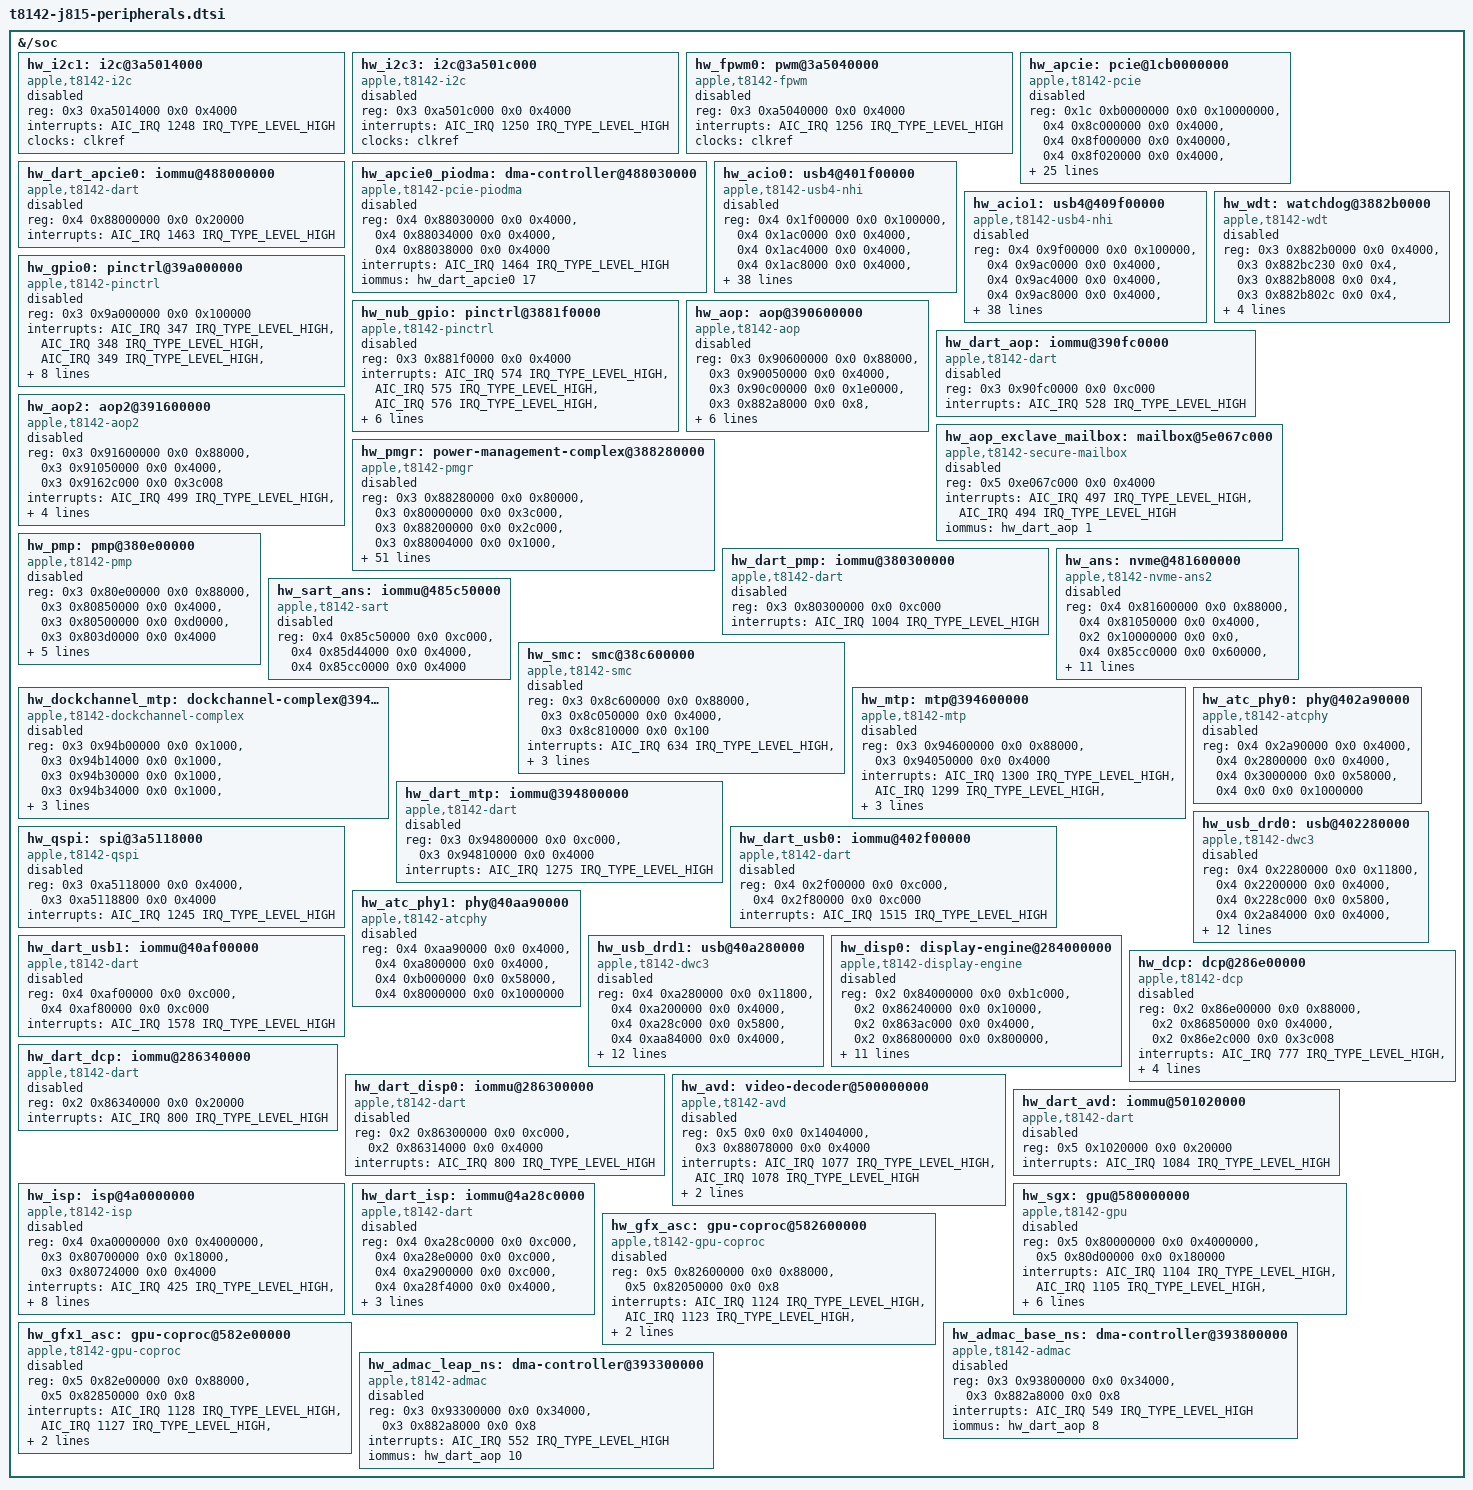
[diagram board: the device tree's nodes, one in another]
#include "t8142-peripherals.dtsi"

// SPDX-License-Identifier: GPL-2.0+ OR MIT
/* Register and interrupt resources; ownership-sensitive blocks stay disabled. */

&{/soc} {

	hw_i2c1: i2c@3a5014000 {
		compatible = "apple,t8142-i2c", "apple,t8103-i2c";
		reg = <0x3 0xa5014000 0x0 0x4000>;
		interrupts = <AIC_IRQ 1248 IRQ_TYPE_LEVEL_HIGH>;
		status = "disabled";
		clocks = <&clkref>;
		#address-cells = <1>;
		#size-cells = <0>;
	};

	hw_i2c3: i2c@3a501c000 {
		compatible = "apple,t8142-i2c", "apple,t8103-i2c";
		reg = <0x3 0xa501c000 0x0 0x4000>;
		interrupts = <AIC_IRQ 1250 IRQ_TYPE_LEVEL_HIGH>;
		status = "disabled";
		clocks = <&clkref>;
		#address-cells = <1>;
		#size-cells = <0>;
	};

	hw_fpwm0: pwm@3a5040000 {
		compatible = "apple,t8142-fpwm", "apple,s5l-fpwm";
		reg = <0x3 0xa5040000 0x0 0x4000>;
		interrupts = <AIC_IRQ 1256 IRQ_TYPE_LEVEL_HIGH>;
		status = "disabled";
		#pwm-cells = <2>;
		clocks = <&clkref>;
	};

	hw_apcie: pcie@1cb0000000 {
		compatible = "apple,t8142-pcie", "apple,pcie";
		reg = <0x1c 0xb0000000 0x0 0x10000000>,
		      <0x4 0x8c000000 0x0 0x4000>,
		      <0x4 0x8f000000 0x0 0x40000>,
		      <0x4 0x8f020000 0x0 0x4000>,
		      <0x4 0x8f040000 0x0 0x20000>,
		      <0x4 0x8e000000 0x0 0x1000000>,
		      <0x4 0x8d044000 0x0 0x4000>,
		      <0x4 0x8d980800 0x0 0x4000>,
		      <0x4 0x88028000 0x0 0x8000>,
		      <0x4 0x8803c000 0x0 0x4000>,
		      <0x4 0x8f010000 0x0 0x4000>,
		      <0x4 0x88024000 0x0 0x4000>,
		      <0x4 0x88048000 0x0 0x4000>,
		      <0x4 0x88044000 0x0 0x4000>,
		      <0x4 0x89028000 0x0 0x8000>,
		      <0x4 0x8903c000 0x0 0x4000>,
		      <0x4 0x8f014000 0x0 0x4000>,
		      <0x4 0x89024000 0x0 0x4000>,
		      <0x4 0x89048000 0x0 0x4000>,
		      <0x4 0x89044000 0x0 0x4000>,
		      <0x4 0x8a028000 0x0 0x8000>,
		      <0x4 0x8a03c000 0x0 0x4000>,
		      <0x4 0x8f018000 0x0 0x4000>,
		      <0x4 0x8a024000 0x0 0x4000>,
		      <0x4 0x8a048000 0x0 0x4000>,
		      <0x4 0x8a044000 0x0 0x4000>;
		interrupts = <AIC_IRQ 1462 IRQ_TYPE_LEVEL_HIGH>,
			     <AIC_IRQ 1471 IRQ_TYPE_LEVEL_HIGH>,
			     <AIC_IRQ 1480 IRQ_TYPE_LEVEL_HIGH>;
		status = "disabled";
	};

	hw_dart_apcie0: iommu@488000000 {
		compatible = "apple,t8142-dart", "apple,dart";
		reg = <0x4 0x88000000 0x0 0x20000>;
		#iommu-cells = <1>;
		interrupts = <AIC_IRQ 1463 IRQ_TYPE_LEVEL_HIGH>;
		status = "disabled";
	};

	hw_apcie0_piodma: dma-controller@488030000 {
		compatible = "apple,t8142-pcie-piodma", "apple,pcie-piodma";
		reg = <0x4 0x88030000 0x0 0x4000>,
		      <0x4 0x88034000 0x0 0x4000>,
		      <0x4 0x88038000 0x0 0x4000>;
		interrupts = <AIC_IRQ 1464 IRQ_TYPE_LEVEL_HIGH>;
		iommus = <&hw_dart_apcie0 17>;
		status = "disabled";
	};

	hw_acio0: usb4@401f00000 {
		compatible = "apple,t8142-usb4-nhi", "apple,usb4-nhi";
		reg = <0x4 0x1f00000 0x0 0x100000>,
		      <0x4 0x1ac0000 0x0 0x4000>,
		      <0x4 0x1ac4000 0x0 0x4000>,
		      <0x4 0x1ac8000 0x0 0x4000>,
		      <0x4 0x1e44000 0x0 0x4000>,
		      <0x4 0x1c80000 0x0 0x4000>;
		interrupts = <AIC_IRQ 1531 IRQ_TYPE_LEVEL_HIGH>,
			     <AIC_IRQ 1532 IRQ_TYPE_LEVEL_HIGH>,
			     <AIC_IRQ 1533 IRQ_TYPE_LEVEL_HIGH>,
			     <AIC_IRQ 1534 IRQ_TYPE_LEVEL_HIGH>,
			     <AIC_IRQ 1535 IRQ_TYPE_LEVEL_HIGH>,
			     <AIC_IRQ 1536 IRQ_TYPE_LEVEL_HIGH>,
			     <AIC_IRQ 1537 IRQ_TYPE_LEVEL_HIGH>,
			     <AIC_IRQ 1538 IRQ_TYPE_LEVEL_HIGH>,
			     <AIC_IRQ 1539 IRQ_TYPE_LEVEL_HIGH>,
			     <AIC_IRQ 1540 IRQ_TYPE_LEVEL_HIGH>,
			     <AIC_IRQ 1541 IRQ_TYPE_LEVEL_HIGH>,
			     <AIC_IRQ 1542 IRQ_TYPE_LEVEL_HIGH>,
			     <AIC_IRQ 1519 IRQ_TYPE_LEVEL_HIGH>,
			     <AIC_IRQ 1520 IRQ_TYPE_LEVEL_HIGH>,
			     <AIC_IRQ 1521 IRQ_TYPE_LEVEL_HIGH>,
			     <AIC_IRQ 1522 IRQ_TYPE_LEVEL_HIGH>,
			     <AIC_IRQ 1523 IRQ_TYPE_LEVEL_HIGH>,
			     <AIC_IRQ 1524 IRQ_TYPE_LEVEL_HIGH>,
			     <AIC_IRQ 1525 IRQ_TYPE_LEVEL_HIGH>,
			     <AIC_IRQ 1526 IRQ_TYPE_LEVEL_HIGH>,
			     <AIC_IRQ 1527 IRQ_TYPE_LEVEL_HIGH>,
			     <AIC_IRQ 1528 IRQ_TYPE_LEVEL_HIGH>,
			     <AIC_IRQ 1529 IRQ_TYPE_LEVEL_HIGH>,
			     <AIC_IRQ 1530 IRQ_TYPE_LEVEL_HIGH>;
		iommus = <&hw_dart_acio0 0>, <&hw_dart_acio0 1>, <&hw_dart_acio0 2>, <&hw_dart_acio0 3>, <&hw_dart_acio0 4>, <&hw_dart_acio0 5>, <&hw_dart_acio0 6>, <&hw_dart_acio0 7>, <&hw_dart_acio0 8>, <&hw_dart_acio0 9>, <&hw_dart_acio0 10>, <&hw_dart_acio0 11>, <&hw_dart_acio0 16>, <&hw_dart_acio0 17>, <&hw_dart_acio0 18>, <&hw_dart_acio0 19>, <&hw_dart_acio0 20>, <&hw_dart_acio0 21>, <&hw_dart_acio0 22>, <&hw_dart_acio0 23>, <&hw_dart_acio0 24>, <&hw_dart_acio0 25>, <&hw_dart_acio0 26>, <&hw_dart_acio0 27>;
		status = "disabled";
	};

	hw_acio1: usb4@409f00000 {
		compatible = "apple,t8142-usb4-nhi", "apple,usb4-nhi";
		reg = <0x4 0x9f00000 0x0 0x100000>,
		      <0x4 0x9ac0000 0x0 0x4000>,
		      <0x4 0x9ac4000 0x0 0x4000>,
		      <0x4 0x9ac8000 0x0 0x4000>,
		      <0x4 0x9e44000 0x0 0x4000>,
		      <0x4 0x9c80000 0x0 0x4000>;
		interrupts = <AIC_IRQ 1594 IRQ_TYPE_LEVEL_HIGH>,
			     <AIC_IRQ 1595 IRQ_TYPE_LEVEL_HIGH>,
			     <AIC_IRQ 1596 IRQ_TYPE_LEVEL_HIGH>,
			     <AIC_IRQ 1597 IRQ_TYPE_LEVEL_HIGH>,
			     <AIC_IRQ 1598 IRQ_TYPE_LEVEL_HIGH>,
			     <AIC_IRQ 1599 IRQ_TYPE_LEVEL_HIGH>,
			     <AIC_IRQ 1600 IRQ_TYPE_LEVEL_HIGH>,
			     <AIC_IRQ 1601 IRQ_TYPE_LEVEL_HIGH>,
			     <AIC_IRQ 1602 IRQ_TYPE_LEVEL_HIGH>,
			     <AIC_IRQ 1603 IRQ_TYPE_LEVEL_HIGH>,
			     <AIC_IRQ 1604 IRQ_TYPE_LEVEL_HIGH>,
			     <AIC_IRQ 1605 IRQ_TYPE_LEVEL_HIGH>,
			     <AIC_IRQ 1582 IRQ_TYPE_LEVEL_HIGH>,
			     <AIC_IRQ 1583 IRQ_TYPE_LEVEL_HIGH>,
			     <AIC_IRQ 1584 IRQ_TYPE_LEVEL_HIGH>,
			     <AIC_IRQ 1585 IRQ_TYPE_LEVEL_HIGH>,
			     <AIC_IRQ 1586 IRQ_TYPE_LEVEL_HIGH>,
			     <AIC_IRQ 1587 IRQ_TYPE_LEVEL_HIGH>,
			     <AIC_IRQ 1588 IRQ_TYPE_LEVEL_HIGH>,
			     <AIC_IRQ 1589 IRQ_TYPE_LEVEL_HIGH>,
			     <AIC_IRQ 1590 IRQ_TYPE_LEVEL_HIGH>,
			     <AIC_IRQ 1591 IRQ_TYPE_LEVEL_HIGH>,
			     <AIC_IRQ 1592 IRQ_TYPE_LEVEL_HIGH>,
			     <AIC_IRQ 1593 IRQ_TYPE_LEVEL_HIGH>;
		iommus = <&hw_dart_acio1 0>, <&hw_dart_acio1 1>, <&hw_dart_acio1 2>, <&hw_dart_acio1 3>, <&hw_dart_acio1 4>, <&hw_dart_acio1 5>, <&hw_dart_acio1 6>, <&hw_dart_acio1 7>, <&hw_dart_acio1 8>, <&hw_dart_acio1 9>, <&hw_dart_acio1 10>, <&hw_dart_acio1 11>, <&hw_dart_acio1 16>, <&hw_dart_acio1 17>, <&hw_dart_acio1 18>, <&hw_dart_acio1 19>, <&hw_dart_acio1 20>, <&hw_dart_acio1 21>, <&hw_dart_acio1 22>, <&hw_dart_acio1 23>, <&hw_dart_acio1 24>, <&hw_dart_acio1 25>, <&hw_dart_acio1 26>, <&hw_dart_acio1 27>;
		status = "disabled";
	};

	hw_wdt: watchdog@3882b0000 {
		compatible = "apple,t8142-wdt", "apple,wdt";
		reg = <0x3 0x882b0000 0x0 0x4000>,
		      <0x3 0x882bc230 0x0 0x4>,
		      <0x3 0x882b8008 0x0 0x4>,
		      <0x3 0x882b802c 0x0 0x4>,
		      <0x3 0x882b8020 0x0 0x4>;
		interrupts = <AIC_IRQ 361 IRQ_TYPE_LEVEL_HIGH>,
			     <AIC_IRQ 0 IRQ_TYPE_LEVEL_HIGH>;
		status = "disabled";
		clocks = <&clkref>;
	};

	hw_gpio0: pinctrl@39a000000 {
		compatible = "apple,t8142-pinctrl", "apple,pinctrl";
		reg = <0x3 0x9a000000 0x0 0x100000>;
		interrupts = <AIC_IRQ 347 IRQ_TYPE_LEVEL_HIGH>,
			     <AIC_IRQ 348 IRQ_TYPE_LEVEL_HIGH>,
			     <AIC_IRQ 349 IRQ_TYPE_LEVEL_HIGH>,
			     <AIC_IRQ 350 IRQ_TYPE_LEVEL_HIGH>,
			     <AIC_IRQ 351 IRQ_TYPE_LEVEL_HIGH>,
			     <AIC_IRQ 352 IRQ_TYPE_LEVEL_HIGH>,
			     <AIC_IRQ 353 IRQ_TYPE_LEVEL_HIGH>;
		#address-cells = <0>;
		gpio-controller;
		#gpio-cells = <2>;
		interrupt-controller;
		#interrupt-cells = <2>;
		status = "disabled";
		gpio-ranges = <&hw_gpio0 0 0 224>;
		apple,npins = <224>;
	};

	hw_nub_gpio: pinctrl@3881f0000 {
		compatible = "apple,t8142-pinctrl", "apple,pinctrl";
		reg = <0x3 0x881f0000 0x0 0x4000>;
		interrupts = <AIC_IRQ 574 IRQ_TYPE_LEVEL_HIGH>,
			     <AIC_IRQ 575 IRQ_TYPE_LEVEL_HIGH>,
			     <AIC_IRQ 576 IRQ_TYPE_LEVEL_HIGH>,
			     <AIC_IRQ 577 IRQ_TYPE_LEVEL_HIGH>,
			     <AIC_IRQ 578 IRQ_TYPE_LEVEL_HIGH>,
			     <AIC_IRQ 579 IRQ_TYPE_LEVEL_HIGH>,
			     <AIC_IRQ 580 IRQ_TYPE_LEVEL_HIGH>;
		#address-cells = <0>;
		gpio-controller;
		#gpio-cells = <2>;
		interrupt-controller;
		#interrupt-cells = <2>;
		status = "disabled";
	};

	hw_aop: aop@390600000 {
		compatible = "apple,t8142-aop", "apple,aop";
		reg = <0x3 0x90600000 0x0 0x88000>,
		      <0x3 0x90050000 0x0 0x4000>,
		      <0x3 0x90c00000 0x0 0x1e0000>,
		      <0x3 0x882a8000 0x0 0x8>,
		      <0x3 0x9062c000 0x0 0x3c008>;
		interrupts = <AIC_IRQ 491 IRQ_TYPE_LEVEL_HIGH>,
			     <AIC_IRQ 490 IRQ_TYPE_LEVEL_HIGH>,
			     <AIC_IRQ 493 IRQ_TYPE_LEVEL_HIGH>,
			     <AIC_IRQ 492 IRQ_TYPE_LEVEL_HIGH>;
		iommus = <&hw_dart_aop 0>;
		status = "disabled";
	};

	hw_dart_aop: iommu@390fc0000 {
		compatible = "apple,t8142-dart", "apple,dart";
		reg = <0x3 0x90fc0000 0x0 0xc000>;
		#iommu-cells = <1>;
		interrupts = <AIC_IRQ 528 IRQ_TYPE_LEVEL_HIGH>;
		status = "disabled";
	};

	hw_aop_exclave_mailbox: mailbox@5e067c000 {
		compatible = "apple,t8142-secure-mailbox", "apple,secure-mailbox";
		reg = <0x5 0xe067c000 0x0 0x4000>;
		interrupts = <AIC_IRQ 497 IRQ_TYPE_LEVEL_HIGH>,
			     <AIC_IRQ 494 IRQ_TYPE_LEVEL_HIGH>;
		iommus = <&hw_dart_aop 1>;
		status = "disabled";
	};

	hw_aop2: aop2@391600000 {
		compatible = "apple,t8142-aop2", "apple,aop2";
		reg = <0x3 0x91600000 0x0 0x88000>,
		      <0x3 0x91050000 0x0 0x4000>,
		      <0x3 0x9162c000 0x0 0x3c008>;
		interrupts = <AIC_IRQ 499 IRQ_TYPE_LEVEL_HIGH>,
			     <AIC_IRQ 498 IRQ_TYPE_LEVEL_HIGH>,
			     <AIC_IRQ 501 IRQ_TYPE_LEVEL_HIGH>,
			     <AIC_IRQ 500 IRQ_TYPE_LEVEL_HIGH>;
		iommus = <&hw_dart_aop 16>;
		status = "disabled";
	};

	hw_pmgr: power-management-complex@388280000 {
		compatible = "apple,t8142-pmgr", "apple,pmgr";
		reg = <0x3 0x88280000 0x0 0x80000>,
		      <0x3 0x80000000 0x0 0x3c000>,
		      <0x3 0x88200000 0x0 0x2c000>,
		      <0x3 0x88004000 0x0 0x1000>,
		      <0x2 0x10e20000 0x0 0x1268>,
		      <0x2 0x10f00000 0x0 0x40088>,
		      <0x2 0x10e40000 0x0 0xc020>,
		      <0x2 0x10e50000 0x0 0x9048>,
		      <0x2 0x10e70000 0x0 0xffe8>,
		      <0x2 0x10050000 0x0 0x9010>,
		      <0x2 0x10150000 0x0 0x9010>,
		      <0x2 0x10250000 0x0 0x9010>,
		      <0x2 0x10350000 0x0 0x9010>,
		      <0x2 0x10450000 0x0 0x9010>,
		      <0x2 0x10550000 0x0 0x9010>,
		      <0x2 0x11e20000 0x0 0x12e8>,
		      <0x2 0x11f00000 0x0 0x40088>,
		      <0x2 0x11e40000 0x0 0xc020>,
		      <0x2 0x11e50000 0x0 0x9048>,
		      <0x2 0x11e70000 0x0 0xffe8>,
		      <0x2 0x11050000 0x0 0x9018>,
		      <0x2 0x11150000 0x0 0x9018>,
		      <0x2 0x11250000 0x0 0x9018>,
		      <0x2 0x11350000 0x0 0x9018>,
		      <0x3 0x80280000 0x0 0x8000>,
		      <0x3 0x88700000 0x0 0x4000>,
		      <0x3 0x88100000 0x0 0xa8000>,
		      <0x4 0x2195c000 0x0 0x4000>,
		      <0x4 0x21960000 0x0 0x4000>,
		      <0x4 0x21974000 0x0 0x4000>,
		      <0x3 0x80208000 0x0 0x8000>,
		      <0x3 0x80700000 0x0 0x18000>,
		      <0x3 0x80728000 0x0 0x4000>,
		      <0x3 0x80724000 0x0 0x4000>,
		      <0x3 0x80764000 0x0 0x4000>,
		      <0x3 0x80780000 0x0 0x4000>,
		      <0x3 0x80760000 0x0 0x4000>,
		      <0x3 0x882b8000 0x0 0x10000>,
		      <0x3 0x882c8000 0x0 0x4000>,
		      <0x3 0x882d0000 0x0 0x8000>,
		      <0x3 0x803c0000 0x0 0x20000>,
		      <0x3 0x80730000 0x0 0x14000>,
		      <0x2 0x11000000 0x0 0xff4000>,
		      <0x4 0x21954000 0x0 0x4000>,
		      <0x3 0x80768000 0x0 0x4000>,
		      <0x3 0x8002c000 0x0 0x4000>,
		      <0x3 0x82000000 0x0 0x1000000>,
		      <0x5 0x80e80000 0x0 0x30000>,
		      <0x5 0x80ec0000 0x0 0x4000>,
		      <0x5 0x80ec0000 0x0 0x8000>,
		      <0x5 0x80e30000 0x0 0x4000>,
		      <0x5 0x80e30000 0x0 0x8000>,
		      <0x2 0x10000000 0x0 0xff4000>;
		interrupts = <AIC_IRQ 1016 IRQ_TYPE_LEVEL_HIGH>,
			     <AIC_IRQ 324 IRQ_TYPE_LEVEL_HIGH>;
		status = "disabled";
	};

	hw_pmp: pmp@380e00000 {
		compatible = "apple,t8142-pmp", "apple,pmp";
		reg = <0x3 0x80e00000 0x0 0x88000>,
		      <0x3 0x80850000 0x0 0x4000>,
		      <0x3 0x80500000 0x0 0xd0000>,
		      <0x3 0x803d0000 0x0 0x4000>;
		interrupts = <AIC_IRQ 1001 IRQ_TYPE_LEVEL_HIGH>,
			     <AIC_IRQ 1000 IRQ_TYPE_LEVEL_HIGH>,
			     <AIC_IRQ 1003 IRQ_TYPE_LEVEL_HIGH>,
			     <AIC_IRQ 1002 IRQ_TYPE_LEVEL_HIGH>;
		iommus = <&hw_dart_pmp 0>;
		status = "disabled";
	};

	hw_dart_pmp: iommu@380300000 {
		compatible = "apple,t8142-dart", "apple,dart";
		reg = <0x3 0x80300000 0x0 0xc000>;
		#iommu-cells = <1>;
		interrupts = <AIC_IRQ 1004 IRQ_TYPE_LEVEL_HIGH>;
		status = "disabled";
	};

	hw_ans: nvme@481600000 {
		compatible = "apple,t8142-nvme-ans2", "apple,nvme-ans";
		reg = <0x4 0x81600000 0x0 0x88000>,
		      <0x4 0x81050000 0x0 0x4000>,
		      <0x2 0x10000000 0x0 0x0>,
		      <0x4 0x85cc0000 0x0 0x60000>,
		      <0x4 0x83000000 0x0 0x1000000>,
		      <0x4 0x85b90000 0x0 0xc000>,
		      <0x4 0x85d47c00 0x0 0x4000>,
		      <0x2 0x10000000 0x0 0x0>,
		      <0x2 0x10000000 0x0 0x0>,
		      <0x4 0xc5cc0000 0x0 0x10000>;
		interrupts = <AIC_IRQ 1144 IRQ_TYPE_LEVEL_HIGH>,
			     <AIC_IRQ 1143 IRQ_TYPE_LEVEL_HIGH>,
			     <AIC_IRQ 1146 IRQ_TYPE_LEVEL_HIGH>,
			     <AIC_IRQ 1145 IRQ_TYPE_LEVEL_HIGH>,
			     <AIC_IRQ 1155 IRQ_TYPE_LEVEL_HIGH>;
		status = "disabled";
	};

	hw_sart_ans: iommu@485c50000 {
		compatible = "apple,t8142-sart", "apple,sart";
		reg = <0x4 0x85c50000 0x0 0xc000>,
		      <0x4 0x85d44000 0x0 0x4000>,
		      <0x4 0x85cc0000 0x0 0x4000>;
		status = "disabled";
	};

	hw_smc: smc@38c600000 {
		compatible = "apple,t8142-smc", "apple,smc";
		reg = <0x3 0x8c600000 0x0 0x88000>,
		      <0x3 0x8c050000 0x0 0x4000>,
		      <0x3 0x8c810000 0x0 0x100>;
		interrupts = <AIC_IRQ 634 IRQ_TYPE_LEVEL_HIGH>,
			     <AIC_IRQ 633 IRQ_TYPE_LEVEL_HIGH>,
			     <AIC_IRQ 636 IRQ_TYPE_LEVEL_HIGH>,
			     <AIC_IRQ 635 IRQ_TYPE_LEVEL_HIGH>;
		status = "disabled";
	};

	hw_dockchannel_mtp: dockchannel-complex@394b00000 {
		compatible = "apple,t8142-dockchannel-complex", "apple,dockchannel-complex";
		reg = <0x3 0x94b00000 0x0 0x1000>,
		      <0x3 0x94b14000 0x0 0x1000>,
		      <0x3 0x94b30000 0x0 0x1000>,
		      <0x3 0x94b34000 0x0 0x1000>,
		      <0x3 0x94b28000 0x0 0x1000>,
		      <0x3 0x94b2c000 0x0 0x1000>;
		interrupts = <AIC_IRQ 1277 IRQ_TYPE_LEVEL_HIGH>;
		status = "disabled";
	};

	hw_mtp: mtp@394600000 {
		compatible = "apple,t8142-mtp", "apple,mtp";
		reg = <0x3 0x94600000 0x0 0x88000>,
		      <0x3 0x94050000 0x0 0x4000>;
		interrupts = <AIC_IRQ 1300 IRQ_TYPE_LEVEL_HIGH>,
			     <AIC_IRQ 1299 IRQ_TYPE_LEVEL_HIGH>,
			     <AIC_IRQ 1302 IRQ_TYPE_LEVEL_HIGH>,
			     <AIC_IRQ 1301 IRQ_TYPE_LEVEL_HIGH>;
		iommus = <&hw_dart_mtp 0>;
		status = "disabled";
	};

	hw_dart_mtp: iommu@394800000 {
		compatible = "apple,t8142-dart", "apple,dart";
		reg = <0x3 0x94800000 0x0 0xc000>,
		      <0x3 0x94810000 0x0 0x4000>;
		#iommu-cells = <1>;
		interrupts = <AIC_IRQ 1275 IRQ_TYPE_LEVEL_HIGH>;
		status = "disabled";
	};

	hw_qspi: spi@3a5118000 {
		compatible = "apple,t8142-qspi", "apple,qspi";
		reg = <0x3 0xa5118000 0x0 0x4000>,
		      <0x3 0xa5118800 0x0 0x4000>;
		interrupts = <AIC_IRQ 1245 IRQ_TYPE_LEVEL_HIGH>;
		status = "disabled";
	};

	hw_atc_phy0: phy@402a90000 {
		compatible = "apple,t8142-atcphy", "apple,atcphy";
		reg = <0x4 0x2a90000 0x0 0x4000>,
		      <0x4 0x2800000 0x0 0x4000>,
		      <0x4 0x3000000 0x0 0x58000>,
		      <0x4 0x0 0x0 0x1000000>;
		status = "disabled";
	};

	hw_dart_usb0: iommu@402f00000 {
		compatible = "apple,t8142-dart", "apple,dart";
		reg = <0x4 0x2f00000 0x0 0xc000>,
		      <0x4 0x2f80000 0x0 0xc000>;
		#iommu-cells = <1>;
		interrupts = <AIC_IRQ 1515 IRQ_TYPE_LEVEL_HIGH>;
		status = "disabled";
	};

	hw_usb_drd0: usb@402280000 {
		compatible = "apple,t8142-dwc3", "apple,dwc3";
		reg = <0x4 0x2280000 0x0 0x11800>,
		      <0x4 0x2200000 0x0 0x4000>,
		      <0x4 0x228c000 0x0 0x5800>,
		      <0x4 0x2a84000 0x0 0x4000>,
		      <0x4 0x2800000 0x0 0x4000>,
		      <0x4 0x2a80000 0x0 0x4000>,
		      <0x4 0x2080000 0x0 0x4000>,
		      <0x4 0x228d000 0x0 0x4000>,
		      <0x4 0x2980000 0x0 0x4000>,
		      <0x3 0x82740000 0x0 0x8>;
		interrupts = <AIC_IRQ 1511 IRQ_TYPE_LEVEL_HIGH>,
			     <AIC_IRQ 1512 IRQ_TYPE_LEVEL_HIGH>,
			     <AIC_IRQ 1513 IRQ_TYPE_LEVEL_HIGH>,
			     <AIC_IRQ 1514 IRQ_TYPE_LEVEL_HIGH>,
			     <AIC_IRQ 1489 IRQ_TYPE_LEVEL_HIGH>;
		iommus = <&hw_dart_usb0 1>;
		status = "disabled";
	};

	hw_atc_phy1: phy@40aa90000 {
		compatible = "apple,t8142-atcphy", "apple,atcphy";
		reg = <0x4 0xaa90000 0x0 0x4000>,
		      <0x4 0xa800000 0x0 0x4000>,
		      <0x4 0xb000000 0x0 0x58000>,
		      <0x4 0x8000000 0x0 0x1000000>;
		status = "disabled";
	};

	hw_dart_usb1: iommu@40af00000 {
		compatible = "apple,t8142-dart", "apple,dart";
		reg = <0x4 0xaf00000 0x0 0xc000>,
		      <0x4 0xaf80000 0x0 0xc000>;
		#iommu-cells = <1>;
		interrupts = <AIC_IRQ 1578 IRQ_TYPE_LEVEL_HIGH>;
		status = "disabled";
	};

	hw_usb_drd1: usb@40a280000 {
		compatible = "apple,t8142-dwc3", "apple,dwc3";
		reg = <0x4 0xa280000 0x0 0x11800>,
		      <0x4 0xa200000 0x0 0x4000>,
		      <0x4 0xa28c000 0x0 0x5800>,
		      <0x4 0xaa84000 0x0 0x4000>,
		      <0x4 0xa800000 0x0 0x4000>,
		      <0x4 0xaa80000 0x0 0x4000>,
		      <0x4 0xa080000 0x0 0x4000>,
		      <0x4 0xa28d000 0x0 0x4000>,
		      <0x4 0xa980000 0x0 0x4000>,
		      <0x3 0x82744000 0x0 0x8>;
		interrupts = <AIC_IRQ 1574 IRQ_TYPE_LEVEL_HIGH>,
			     <AIC_IRQ 1575 IRQ_TYPE_LEVEL_HIGH>,
			     <AIC_IRQ 1576 IRQ_TYPE_LEVEL_HIGH>,
			     <AIC_IRQ 1577 IRQ_TYPE_LEVEL_HIGH>,
			     <AIC_IRQ 1552 IRQ_TYPE_LEVEL_HIGH>;
		iommus = <&hw_dart_usb1 1>;
		status = "disabled";
	};

	hw_disp0: display-engine@284000000 {
		compatible = "apple,t8142-display-engine", "apple,display-engine";
		reg = <0x2 0x84000000 0x0 0xb1c000>,
		      <0x2 0x86240000 0x0 0x10000>,
		      <0x2 0x863ac000 0x0 0x4000>,
		      <0x2 0x86800000 0x0 0x800000>,
		      <0x3 0x82700000 0x0 0x114000>;
		interrupts = <AIC_IRQ 791 IRQ_TYPE_LEVEL_HIGH>,
			     <AIC_IRQ 837 IRQ_TYPE_LEVEL_HIGH>,
			     <AIC_IRQ 794 IRQ_TYPE_LEVEL_HIGH>,
			     <AIC_IRQ 793 IRQ_TYPE_LEVEL_HIGH>,
			     <AIC_IRQ 792 IRQ_TYPE_LEVEL_HIGH>,
			     <AIC_IRQ 799 IRQ_TYPE_LEVEL_HIGH>,
			     <AIC_IRQ 789 IRQ_TYPE_LEVEL_HIGH>,
			     <AIC_IRQ 803 IRQ_TYPE_LEVEL_HIGH>,
			     <AIC_IRQ 798 IRQ_TYPE_LEVEL_HIGH>;
		iommus = <&hw_dart_disp0 0>, <&hw_dart_disp0 16>;
		status = "disabled";
	};

	hw_dcp: dcp@286e00000 {
		compatible = "apple,t8142-dcp", "apple,dcp";
		reg = <0x2 0x86e00000 0x0 0x88000>,
		      <0x2 0x86850000 0x0 0x4000>,
		      <0x2 0x86e2c000 0x0 0x3c008>;
		interrupts = <AIC_IRQ 777 IRQ_TYPE_LEVEL_HIGH>,
			     <AIC_IRQ 776 IRQ_TYPE_LEVEL_HIGH>,
			     <AIC_IRQ 779 IRQ_TYPE_LEVEL_HIGH>,
			     <AIC_IRQ 778 IRQ_TYPE_LEVEL_HIGH>;
		iommus = <&hw_dart_dcp 23>;
		status = "disabled";
	};

	hw_dart_dcp: iommu@286340000 {
		compatible = "apple,t8142-dart", "apple,dart";
		reg = <0x2 0x86340000 0x0 0x20000>;
		#iommu-cells = <1>;
		interrupts = <AIC_IRQ 800 IRQ_TYPE_LEVEL_HIGH>;
		status = "disabled";
	};

	hw_dart_disp0: iommu@286300000 {
		compatible = "apple,t8142-dart", "apple,dart";
		reg = <0x2 0x86300000 0x0 0xc000>,
		      <0x2 0x86314000 0x0 0x4000>;
		#iommu-cells = <1>;
		interrupts = <AIC_IRQ 800 IRQ_TYPE_LEVEL_HIGH>;
		status = "disabled";
	};

	hw_avd: video-decoder@500000000 {
		compatible = "apple,t8142-avd", "apple,avd";
		reg = <0x5 0x0 0x0 0x1404000>,
		      <0x3 0x88078000 0x0 0x4000>;
		interrupts = <AIC_IRQ 1077 IRQ_TYPE_LEVEL_HIGH>,
			     <AIC_IRQ 1078 IRQ_TYPE_LEVEL_HIGH>;
		iommus = <&hw_dart_avd 0>, <&hw_dart_avd 1>, <&hw_dart_avd 2>;
		status = "disabled";
	};

	hw_dart_avd: iommu@501020000 {
		compatible = "apple,t8142-dart", "apple,dart";
		reg = <0x5 0x1020000 0x0 0x20000>;
		#iommu-cells = <1>;
		interrupts = <AIC_IRQ 1084 IRQ_TYPE_LEVEL_HIGH>;
		status = "disabled";
	};

	hw_isp: isp@4a0000000 {
		compatible = "apple,t8142-isp", "apple,isp";
		reg = <0x4 0xa0000000 0x0 0x4000000>,
		      <0x3 0x80700000 0x0 0x18000>,
		      <0x3 0x80724000 0x0 0x4000>;
		interrupts = <AIC_IRQ 425 IRQ_TYPE_LEVEL_HIGH>,
			     <AIC_IRQ 426 IRQ_TYPE_LEVEL_HIGH>,
			     <AIC_IRQ 427 IRQ_TYPE_LEVEL_HIGH>,
			     <AIC_IRQ 428 IRQ_TYPE_LEVEL_HIGH>,
			     <AIC_IRQ 438 IRQ_TYPE_LEVEL_HIGH>;
		iommus = <&hw_dart_isp 0>, <&hw_dart_isp 12>, <&hw_dart_isp 4>, <&hw_dart_isp 5>, <&hw_dart_isp 8>, <&hw_dart_isp 9>, <&hw_dart_isp 4>, <&hw_dart_isp 5>, <&hw_dart_isp 8>, <&hw_dart_isp 9>;
		status = "disabled";
	};

	hw_dart_isp: iommu@4a28c0000 {
		compatible = "apple,t8142-dart", "apple,dart";
		reg = <0x4 0xa28c0000 0x0 0xc000>,
		      <0x4 0xa28e0000 0x0 0xc000>,
		      <0x4 0xa2900000 0x0 0xc000>,
		      <0x4 0xa28f4000 0x0 0x4000>,
		      <0x4 0xa2914000 0x0 0x4000>,
		      <0x4 0xa28d0000 0x0 0x4000>;
		#iommu-cells = <1>;
		interrupts = <AIC_IRQ 443 IRQ_TYPE_LEVEL_HIGH>;
		status = "disabled";
	};

	hw_sgx: gpu@580000000 {
		compatible = "apple,t8142-gpu", "apple,gpu";
		reg = <0x5 0x80000000 0x0 0x4000000>,
		      <0x5 0x80d00000 0x0 0x180000>;
		interrupts = <AIC_IRQ 1104 IRQ_TYPE_LEVEL_HIGH>,
			     <AIC_IRQ 1105 IRQ_TYPE_LEVEL_HIGH>,
			     <AIC_IRQ 1106 IRQ_TYPE_LEVEL_HIGH>,
			     <AIC_IRQ 1107 IRQ_TYPE_LEVEL_HIGH>,
			     <AIC_IRQ 1131 IRQ_TYPE_LEVEL_HIGH>,
			     <AIC_IRQ 1133 IRQ_TYPE_LEVEL_HIGH>,
			     <AIC_IRQ 1119 IRQ_TYPE_LEVEL_HIGH>,
			     <AIC_IRQ 1121 IRQ_TYPE_LEVEL_HIGH>;
		status = "disabled";
	};

	hw_gfx_asc: gpu-coproc@582600000 {
		compatible = "apple,t8142-gpu-coproc", "apple,gpu-coproc";
		reg = <0x5 0x82600000 0x0 0x88000>,
		      <0x5 0x82050000 0x0 0x8>;
		interrupts = <AIC_IRQ 1124 IRQ_TYPE_LEVEL_HIGH>,
			     <AIC_IRQ 1123 IRQ_TYPE_LEVEL_HIGH>,
			     <AIC_IRQ 1126 IRQ_TYPE_LEVEL_HIGH>,
			     <AIC_IRQ 1125 IRQ_TYPE_LEVEL_HIGH>;
		status = "disabled";
	};

	hw_gfx1_asc: gpu-coproc@582e00000 {
		compatible = "apple,t8142-gpu-coproc", "apple,gpu-coproc";
		reg = <0x5 0x82e00000 0x0 0x88000>,
		      <0x5 0x82850000 0x0 0x8>;
		interrupts = <AIC_IRQ 1128 IRQ_TYPE_LEVEL_HIGH>,
			     <AIC_IRQ 1127 IRQ_TYPE_LEVEL_HIGH>,
			     <AIC_IRQ 1130 IRQ_TYPE_LEVEL_HIGH>,
			     <AIC_IRQ 1129 IRQ_TYPE_LEVEL_HIGH>;
		status = "disabled";
	};

	hw_admac_base_ns: dma-controller@393800000 {
		compatible = "apple,t8142-admac", "apple,admac";
		reg = <0x3 0x93800000 0x0 0x34000>,
		      <0x3 0x882a8000 0x0 0x8>;
		interrupts = <AIC_IRQ 549 IRQ_TYPE_LEVEL_HIGH>;
		iommus = <&hw_dart_aop 8>;
		status = "disabled";
		#dma-cells = <1>;
	};

	hw_admac_leap_ns: dma-controller@393300000 {
		compatible = "apple,t8142-admac", "apple,admac";
		reg = <0x3 0x93300000 0x0 0x34000>,
		      <0x3 0x882a8000 0x0 0x8>;
		interrupts = <AIC_IRQ 552 IRQ_TYPE_LEVEL_HIGH>;
		iommus = <&hw_dart_aop 10>;
		status = "disabled";
		#dma-cells = <1>;
	};


};
